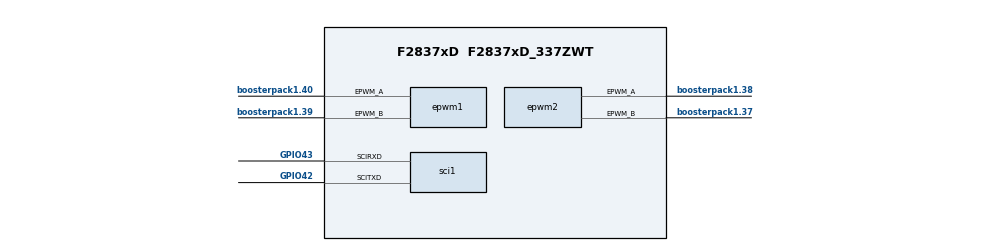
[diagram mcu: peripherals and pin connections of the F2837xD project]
/**
 * @cliArgs --board "/boards/LAUNCHXL_F28379D" --device "F2837xD" --part "F2837xD_337ZWT" --package "F2837xD_337ZWT" --context "CPU1" --product "C2000WARE@5.04.00.00"
 * @versions {"tool":"1.22.0+3893"}
 */

/**
 * Import the modules used in this configuration.
 */
const adc              = scripting.addModule("/driverlib/adc.js", {}, false);
const adc1             = adc.addInstance();
const adc2             = adc.addInstance();
const led              = scripting.addModule("/driverlib/board_components/led", {}, false);
const led1             = led.addInstance();
const led2             = led.addInstance();
const ecap             = scripting.addModule("/driverlib/ecap.js", {}, false);
const ecap1            = ecap.addInstance();
const epwm             = scripting.addModule("/driverlib/epwm.js", {}, false);
const epwm1            = epwm.addInstance();
const epwm2            = epwm.addInstance();
const inputxbar        = scripting.addModule("/driverlib/inputxbar.js", {}, false);
const inputxbar1       = inputxbar.addInstance();
const inputxbar_input  = scripting.addModule("/driverlib/inputxbar_input.js");
const inputxbar_input1 = inputxbar_input.addInstance();
const sci              = scripting.addModule("/driverlib/sci.js", {}, false);
const sci1             = sci.addInstance();

/**
 * Write custom configuration values to the imported modules.
 */
adc1.$name                          = "myADC0";
adc1.adcClockPrescaler              = "ADC_CLK_DIV_4_0";
adc1.enabledSOCs                    = ["ADC_SOC_NUMBER0"];
adc1.enabledInts                    = ["ADC_INT_NUMBER1"];
adc1.enableInterrupt1               = true;
adc1.enableInterrupt1ContinuousMode = true;
adc1.registerInterrupts             = ["1"];
adc1.soc0Trigger                    = "ADC_TRIGGER_EPWM2_SOCA";
adc1.soc0SampleWindow               = 8;
adc1.interruptPulseMode             = "ADC_PULSE_END_OF_CONV";
adc1.adcInt1.interruptHandler       = "adcA1ISR";
adc1.adcInt1.enableInterrupt        = true;

adc2.$name                          = "myADC1";
adc2.adcBase                        = "ADCB_BASE";
adc2.adcClockPrescaler              = "ADC_CLK_DIV_4_0";
adc2.enabledSOCs                    = ["ADC_SOC_NUMBER0"];
adc2.soc0SampleWindow               = 8;
adc2.soc0Channel                    = "ADC_CH_ADCIN2";
adc2.enabledInts                    = ["ADC_INT_NUMBER1"];
adc2.enableInterrupt1               = true;
adc2.enableInterrupt1ContinuousMode = true;
adc2.soc0Trigger                    = "ADC_TRIGGER_EPWM2_SOCA";

led1.$name     = "myBoardLED0";
led1.$hardware = system.deviceData.board.components.LED5;

led2.$name     = "myBoardLED1";
led2.$hardware = system.deviceData.board.components.LED4;

ecap1.$name                    = "myECAP0";
ecap1.eventStop                = "ECAP_EVENT_4";
ecap1.eventTwoPolarity         = "ECAP_EVNT_FALLING_EDGE";
ecap1.eventFourPolarity        = "ECAP_EVNT_FALLING_EDGE";
ecap1.registerInterrupts       = true;
ecap1.enableInterrupt          = true;
ecap1.interruptSourceCapture   = ["ECAP_ISR_SOURCE_CAPTURE_EVENT_3"];
ecap1.ecapInt.interruptHandler = "ecap1ISR";
ecap1.ecapInt.enableInterrupt  = true;

epwm1.$name                                                      = "myEPWM0";
epwm1.epwmTimebase_counterMode                                   = "EPWM_COUNTER_MODE_UP_DOWN";
epwm1.epwmCounterCompare_cmpA                                    = 18750;
epwm1.epwmTimebase_period                                        = 25000;
epwm1.epwmActionQualifier_EPWM_AQ_OUTPUT_A_shadowMode            = true;
epwm1.epwmActionQualifier_EPWM_AQ_OUTPUT_A_ON_TIMEBASE_UP_CMPA   = "EPWM_AQ_OUTPUT_HIGH";
epwm1.epwmActionQualifier_EPWM_AQ_OUTPUT_A_ON_TIMEBASE_DOWN_CMPA = "EPWM_AQ_OUTPUT_LOW";
epwm1.epwmDeadband_polarityFED                                   = "EPWM_DB_POLARITY_ACTIVE_LOW";
epwm1.epwmDeadband_enableRED                                     = true;
epwm1.epwmDeadband_enableFED                                     = true;
epwm1.epwmDeadband_delayRED                                      = 100;
epwm1.epwmDeadband_delayFED                                      = 80;
epwm1.epwm.$assign                                               = "EPWM1";
epwm1.epwm.epwm_aPin.$assign                                     = "boosterpack1.40";
epwm1.epwm.epwm_bPin.$assign                                     = "boosterpack1.39";

epwm2.$name                                             = "myEPWM2";
epwm2.epwmTimebase_period                               = 1999;
epwm2.epwmTimebase_counterMode                          = "EPWM_COUNTER_MODE_UP";
epwm2.epwmEventTrigger_EPWM_SOC_A_triggerEnable         = true;
epwm2.epwmEventTrigger_EPWM_SOC_A_triggerSource         = "EPWM_SOC_TBCTR_PERIOD";
epwm2.epwmEventTrigger_EPWM_SOC_A_triggerEventPrescalar = "1";
epwm2.epwmEventTrigger_EPWM_SOC_B_triggerEnable         = true;
epwm2.epwmEventTrigger_EPWM_SOC_B_triggerSource         = "EPWM_SOC_TBCTR_PERIOD";
epwm2.epwmEventTrigger_EPWM_SOC_B_triggerEventPrescalar = "1";
epwm2.epwm.$assign                                      = "EPWM2";
epwm2.epwm.epwm_aPin.$assign                            = "boosterpack1.38";
epwm2.epwm.epwm_bPin.$assign                            = "boosterpack1.37";

inputxbar1.$name = "myINPUTXBAR0";

inputxbar_input1.$name          = "myINPUTXBARINPUT0";
inputxbar_input1.inputxbarInput = "XBAR_INPUT7";

sci1.$name                      = "mySCIA";
sci1.selectRegisteredInterrupts = ["registerRxInt"];
sci1.baudRates                  = 9600;
sci1.rxFifo                     = "SCI_FIFO_RX1";
sci1.enabledFIFOInterrupts      = ["SCI_INT_RXFF"];
sci1.sci.scirxdPin.$assign      = "GPIO43";
sci1.sci.scitxdPin.$assign      = "GPIO42";
sci1.rxQual.$name               = "myGPIOQUAL0";
sci1.txQual.$name               = "myGPIOQUAL1";
sci1.sciRXInt.enableInterrupt   = true;

/**
 * Pinmux solution for unlocked pins/peripherals. This ensures that minor changes to the automatic solver in a future
 * version of the tool will not impact the pinmux you originally saw.  These lines can be completely deleted in order to
 * re-solve from scratch.
 */
led1.gpio.gpioPin.$suggestSolution = "GPIO34";
led2.gpio.gpioPin.$suggestSolution = "GPIO31";
sci1.sci.$suggestSolution          = "SCIA";
